# f29h85x_xbar_regs register map
Vendor: Texas Instruments
Peripheral module from a debugger description file (folder C29).
Registers are 32-bit, read-only, no defined reset value unless marked. A register's access mark holds for its fields unless they carry their own. Offsets are as the file gives them; lines under a group give offsets from that group; [hi:lo] are bit positions; {n}, {i} and the like mark numbered series; 'fields as' and 'values as' point back to an identical list; <NAME> marks a mode.

## XBAR_REGS — XBAR Registers
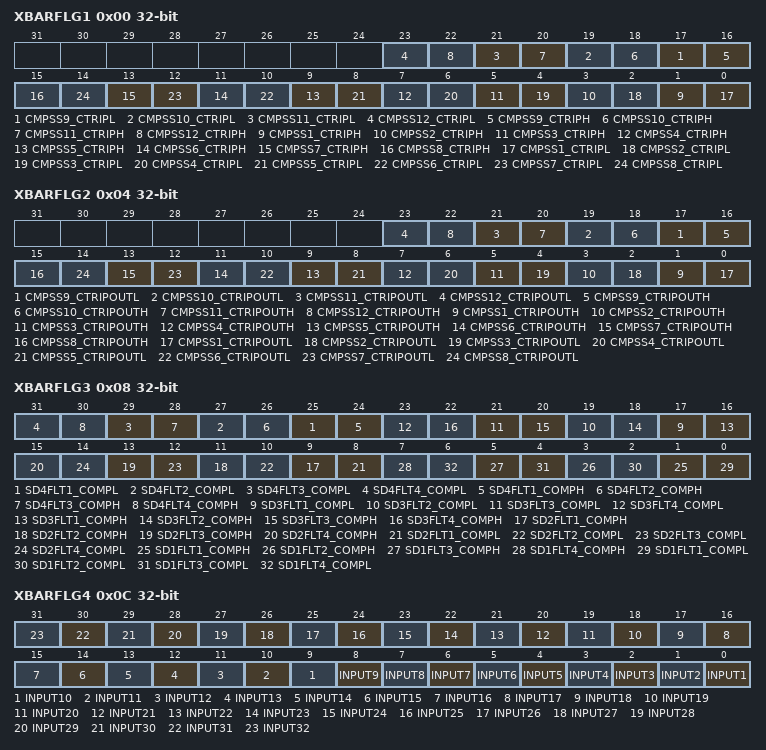
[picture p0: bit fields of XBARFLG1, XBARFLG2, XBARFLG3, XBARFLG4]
0x00 XBARFLG1 — X-Bar Input Flag Register 1
  [2n-1] CMPSS{n}_CTRIPL (n=9..12) — Input Flag for CMPSS{n}_CTRIPL Signal
  [2n-2] CMPSS{n}_CTRIPH (n=9..12) — Input Flag for CMPSS{n}_CTRIPH Signal
  [2n-1] CMPSS{n}_CTRIPH (n=1..8) — Input Flag for CMPSS{n}_CTRIPH Signal
  [2n-2] CMPSS{n}_CTRIPL (n=1..8) — Input Flag for CMPSS{n}_CTRIPL Signal
0x04 XBARFLG2 — X-Bar Input Flag Register 2
  [2n-1] CMPSS{n}_CTRIPOUTL (n=9..12) — Input Flag for CMPSS{n}_CTRIPOUTL Signal
  [2n-2] CMPSS{n}_CTRIPOUTH (n=9..12) — Input Flag for CMPSS{n}_CTRIPOUTH Signal
  [2n-1] CMPSS{n}_CTRIPOUTH (n=1..8) — Input Flag for CMPSS{n}_CTRIPOUTH Signal
  [2n-2] CMPSS{n}_CTRIPOUTL (n=1..8) — Input Flag for CMPSS{n}_CTRIPOUTL Signal
0x08 XBARFLG3 — X-Bar Input Flag Register 3
  [2n+23] SD4FLT{n}_COMPL (n=1..4) — Input Flag for SD4FLT{n}_COMPL Signal
  [2n+22] SD4FLT{n}_COMPH (n=1..4) — Input Flag for SD4FLT{n}_COMPH Signal
  [2n+15] SD3FLT{n}_COMPL (n=1..4) — Input Flag for SD3FLT{n}_COMPL Signal
  [2n+14] SD3FLT{n}_COMPH (n=1..4) — Input Flag for SD3FLT{n}_COMPH Signal
  [2n+7] SD2FLT{n}_COMPH (n=1..4) — Input Flag for SD2FLT{n}_COMPH Signal
  [2n+6] SD2FLT{n}_COMPL (n=1..4) — Input Flag for SD2FLT{n}_COMPL Signal
  [2n-1] SD1FLT{n}_COMPH (n=1..4) — Input Flag for SD1FLT{n}_COMPH Signal
  [2n-2] SD1FLT{n}_COMPL (n=1..4) — Input Flag for SD1FLT{n}_COMPL Signal
0x0C XBARFLG4 — X-Bar Input Flag Register 4
  [n-1] INPUT{n} (n=1..32) — Input Flag for INPUT{n} Signal
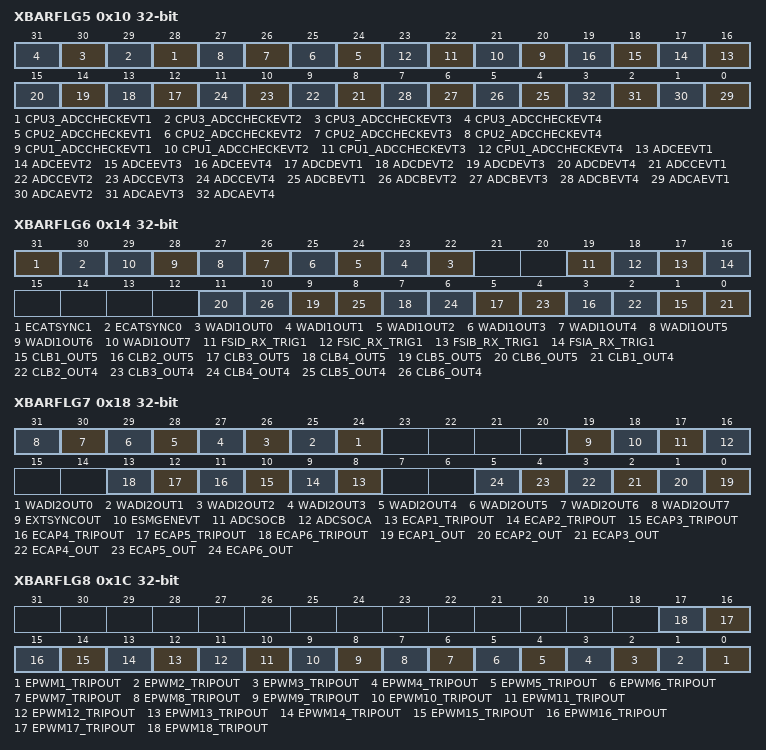
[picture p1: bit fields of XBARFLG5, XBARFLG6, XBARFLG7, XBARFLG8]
0x10 XBARFLG5 — X-Bar Input Flag Register 5
  [n+27] CPU3_ADCCHECKEVT{n} (n=1..4) — Input Flag for CPU3_ADCCHECKEVT{n} Signal
  [n+23] CPU2_ADCCHECKEVT{n} (n=1..4) — Input Flag for CPU2_ADCCHECKEVT{n} Signal
  [n+19] CPU1_ADCCHECKEVT{n} (n=1..4) — Input Flag for CPU1_ADCCHECKEVT{n} Signal
  [n+15] ADCEEVT{n} (n=1..4) — Input Flag for ADCEEVT{n} Signal
  [n+11] ADCDEVT{n} (n=1..4) — Input Flag for ADCDEVT{n} Signal
  [n+7] ADCCEVT{n} (n=1..4) — Input Flag for ADCCEVT{n} Signal
  [n+3] ADCBEVT{n} (n=1..4) — Input Flag for ADCBEVT{n} Signal
  [n-1] ADCAEVT{n} (n=1..4) — Input Flag for ADCAEVT{n} Signal
0x14 XBARFLG6 — X-Bar Input Flag Register 6
  [31] ECATSYNC1 — Input Latch for ECATSYNC1 Signal
  [30] ECATSYNC0 — Input Latch for ECATSYNC0 Signal
  [n+22] WADI1OUT{n} (n=0..7) — Input Flag for WADI1OUT{n} Signal
  [19] FSID_RX_TRIG1 — Input Flag for FSID_RX_TRIG1 Signal
  [18] FSIC_RX_TRIG1 — Input Flag for FSIC_RX_TRIG1 Signal
  [17] FSIB_RX_TRIG1 — Input Flag for FSIB_RX_TRIG1 Signal
  [16] FSIA_RX_TRIG1 — Input Flag for FSIA_RX_TRIG1 Signal
  [2n-1] CLB{n}_OUT5 (n=1..6) — Input Latch for CLB{n}_OUT5 Signal
  [2n-2] CLB{n}_OUT4 (n=1..6) — Input Latch for CLB{n}_OUT4 Signal
0x18 XBARFLG7 — X-Bar Input Flag Register 7
  [n+24] WADI2OUT{n} (n=0..7) — Input Flag for WADI2OUT{n} Signal
  [19] EXTSYNCOUT — Input Flag for EXTSYNCOUT Signal
  [18] ESMGENEVT — Input Flag for ESMGENEVT Signal
  [17] ADCSOCB — Input Flag for ADCSOCB Signal
  [16] ADCSOCA — Input Flag for ADCSOCA Signal
  [n+7] ECAP{n}_TRIPOUT (n=1..6) — Input Flag for ECAP{n}_TRIPOUT Signal
  [n-1] ECAP{n}_OUT (n=1..6) — Input Flag for ECAP{n}_OUT Signal
0x1C XBARFLG8 — X-Bar Input Flag Register 8
  [n-1] EPWM{n}_TRIPOUT (n=1..18) — Input Flag for EPWM{n}_TRIPOUT Signal
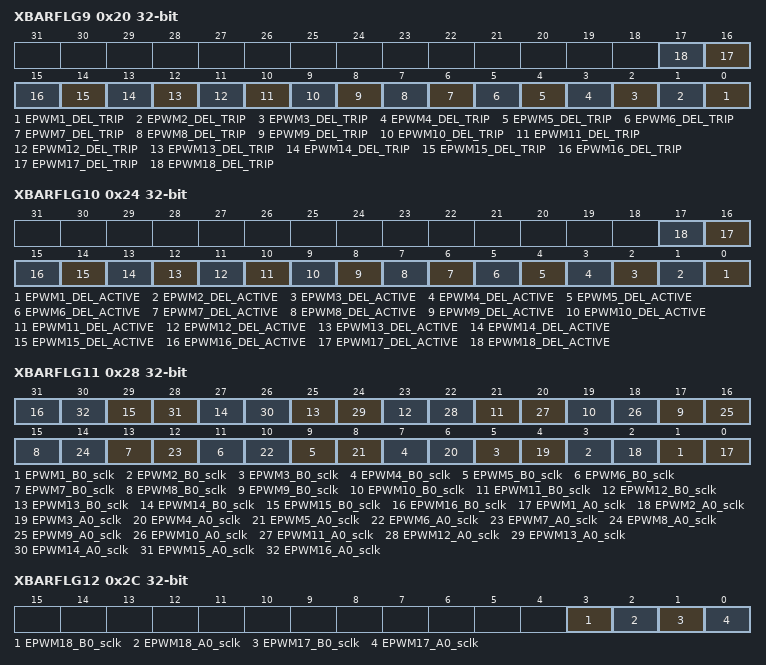
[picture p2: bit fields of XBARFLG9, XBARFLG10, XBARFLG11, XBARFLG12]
0x20 XBARFLG9 — X-Bar Input Flag Register 9
  [n-1] EPWM{n}_DEL_TRIP (n=1..18) — Input Flag for EPWM{n}_DEL_TRIP Signal
0x24 XBARFLG10 — X-Bar Input Flag Register 10
  [n-1] EPWM{n}_DEL_ACTIVE (n=1..18) — Input Flag for EPWM{n}_DEL_ACTIVE Signal
0x28 XBARFLG11 — X-Bar Input Flag Register 11
  [2n-1] EPWM{n}_B0_sclk (n=1..16) — Input Flag for EPWM{n}_B0_sclk Signal
  [2n-2] EPWM{n}_A0_sclk (n=1..16) — Input Flag for EPWM{n}_A0_sclk Signal
0x2C XBARFLG12 — X-Bar Input Flag Register 12
  [3] EPWM18_B0_sclk — Input Flag for EPWM18_B0_sclk Signal
  [2] EPWM18_A0_sclk — Input Flag for EPWM18_A0_sclk Signal
  [1] EPWM17_B0_sclk — Input Flag for EPWM17_B0_sclk Signal
  [0] EPWM17_A0_sclk — Input Flag for EPWM17_A0_sclk Signal
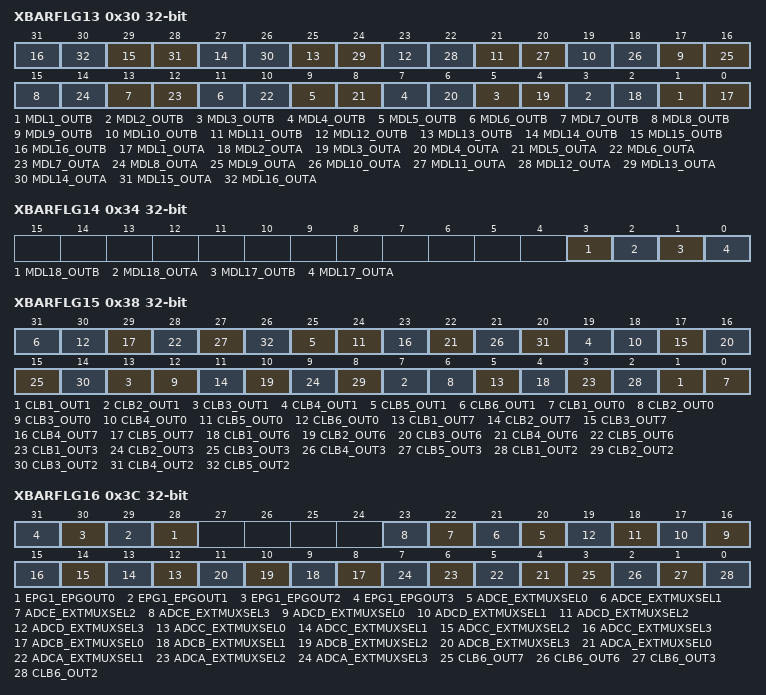
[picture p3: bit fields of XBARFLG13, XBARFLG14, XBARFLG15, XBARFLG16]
0x30 XBARFLG13 — X-Bar Input Flag Register 13
  [2n-1] MDL{n}_OUTB (n=1..16) — Input Flag for MDL{n}_OUTB Signal
  [2n-2] MDL{n}_OUTA (n=1..16) — Input Flag for MDL{n}_OUTA Signal
0x34 XBARFLG14 — X-Bar Input Flag Register 14
  [3] MDL18_OUTB — Input Flag for MDL18_OUTB Signal
  [2] MDL18_OUTA — Input Flag for MDL18_OUTA Signal
  [1] MDL17_OUTB — Input Flag for MDL17_OUTB Signal
  [0] MDL17_OUTA — Input Flag for MDL17_OUTA Signal
0x38 XBARFLG15 — X-Bar Input Flag Register 15
  [6n-5] CLB{n}_OUT1 (n=1..6) — Input Flag for CLB{n}_OUT1 Signal
  [6n-6] CLB{n}_OUT0 (n=1..6) — Input Flag for CLB{n}_OUT0 Signal
  [6n-1] CLB{n}_OUT7 (n=1..5) — Input Flag for CLB{n}_OUT7 Signal
  [6n-2] CLB{n}_OUT6 (n=1..5) — Input Flag for CLB{n}_OUT6 Signal
  [6n-3] CLB{n}_OUT3 (n=1..5) — Input Flag for CLB{n}_OUT3 Signal
  [6n-4] CLB{n}_OUT2 (n=1..5) — Input Flag for CLB{n}_OUT2 Signal
0x3C XBARFLG16 — X-Bar Input Flag Register 16
  [n+28] EPG1_EPGOUT{n} (n=0..3) — Input Flag for EPG1_EPGOUT{n} Signal
  [n+20] ADCE_EXTMUXSEL{n} (n=0..3) — Input Flag for ADCE_EXTMUXSEL{n} Signal
  [n+16] ADCD_EXTMUXSEL{n} (n=0..3) — Input Flag for ADCD_EXTMUXSEL{n} Signal
  [n+12] ADCC_EXTMUXSEL{n} (n=0..3) — Input Flag for ADCC_EXTMUXSEL{n} Signal
  [n+8] ADCB_EXTMUXSEL{n} (n=0..3) — Input Flag for ADCB_EXTMUXSEL{n} Signal
  [n+4] ADCA_EXTMUXSEL{n} (n=0..3) — Input Flag for ADCA_EXTMUXSEL{n} Signal
  [3] CLB6_OUT7 — Input Flag for CLB6_OUT7 Signal
  [2] CLB6_OUT6 — Input Flag for CLB6_OUT6 Signal
  [1] CLB6_OUT3 — Input Flag for CLB6_OUT3 Signal
  [0] CLB6_OUT2 — Input Flag for CLB6_OUT2 Signal
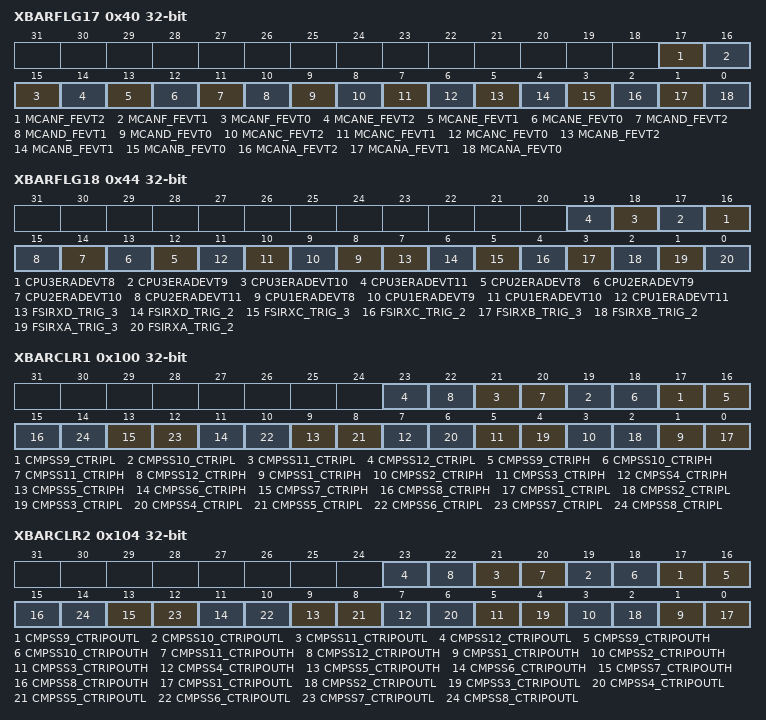
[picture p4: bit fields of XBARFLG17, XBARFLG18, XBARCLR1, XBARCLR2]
0x40 XBARFLG17 — X-Bar Input Flag Register 16
  [17] MCANF_FEVT2 — Input Flag for MCANF_FEVT2 Signal
  [16] MCANF_FEVT1 — Input Flag for MCANF_FEVT1 Signal
  [15] MCANF_FEVT0 — Input Flag for MCANF_FEVT0 Signal
  [14] MCANE_FEVT2 — Input Flag for MCANE_FEVT2 Signal
  [13] MCANE_FEVT1 — Input Flag for MCANE_FEVT1 Signal
  [12] MCANE_FEVT0 — Input Flag for MCANE_FEVT0 Signal
  [11] MCAND_FEVT2 — Input Flag for MCAND_FEVT2 Signal
  [10] MCAND_FEVT1 — Input Flag for MCAND_FEVT1 Signal
  [9] MCAND_FEVT0 — Input Flag for MCAND_FEVT0 Signal
  [8] MCANC_FEVT2 — Input Flag for MCANC_FEVT2 Signal
  [7] MCANC_FEVT1 — Input Flag for MCANC_FEVT1 Signal
  [6] MCANC_FEVT0 — Input Flag for MCANC_FEVT0 Signal
  [5] MCANB_FEVT2 — Input Flag for MCANB_FEVT2 Signal
  [4] MCANB_FEVT1 — Input Flag for MCANB_FEVT1 Signal
  [3] MCANB_FEVT0 — Input Flag for MCANB_FEVT0 Signal
  [2] MCANA_FEVT2 — Input Flag for MCANA_FEVT2 Signal
  [1] MCANA_FEVT1 — Input Flag for MCANA_FEVT1 Signal
  [0] MCANA_FEVT0 — Input Flag for MCANA_FEVT0 Signal
0x44 XBARFLG18 — X-Bar Input Flag Register 16
  [n+8] CPU3ERADEVT{n} (n=8..11) — Input Flag for CPU3ERADEVT{n} Signal
  [n+4] CPU2ERADEVT{n} (n=8..11) — Input Flag for CPU2ERADEVT{n} Signal
  [n] CPU1ERADEVT{n} (n=8..11) — Input Flag for CPU1ERADEVT{n} Signal
  [7] FSIRXD_TRIG_3 — Input Flag for FSIRXD_TRIG_3 Signal
  [6] FSIRXD_TRIG_2 — Input Flag for FSIRXD_TRIG_2 Signal
  [5] FSIRXC_TRIG_3 — Input Flag for FSIRXC_TRIG_3 Signal
  [4] FSIRXC_TRIG_2 — Input Flag for FSIRXC_TRIG_2 Signal
  [3] FSIRXB_TRIG_3 — Input Flag for FSIRXB_TRIG_3 Signal
  [2] FSIRXB_TRIG_2 — Input Flag for FSIRXB_TRIG_2 Signal
  [1] FSIRXA_TRIG_3 — Input Flag for FSIRXA_TRIG_3 Signal
  [0] FSIRXA_TRIG_2 — Input Flag for FSIRXA_TRIG_2 Signal
0x100 XBARCLR1 rw — X-Bar Input Flag Clear Register 1
  [2n-1] CMPSS{n}_CTRIPL (n=9..12) — Input Flag Clear for CMPSS{n}_CTRIPL Signal
  [2n-2] CMPSS{n}_CTRIPH (n=9..12) — Input Flag Clear for CMPSS{n}_CTRIPH Signal
  [2n-1] CMPSS{n}_CTRIPH (n=1..8) — Input Flag Clear for CMPSS{n}_CTRIPH Signal
  [2n-2] CMPSS{n}_CTRIPL (n=1..8) — Input Flag Clear for CMPSS{n}_CTRIPL Signal
0x104 XBARCLR2 rw — X-Bar Input Flag Clear Register 2
  [2n-1] CMPSS{n}_CTRIPOUTL (n=9..12) — Input Flag clear for CMPSS{n}_CTRIPOUTL Signal
  [2n-2] CMPSS{n}_CTRIPOUTH (n=9..12) — Input Flag clear for CMPSS{n}_CTRIPOUTH Signal
  [2n-1] CMPSS{n}_CTRIPOUTH (n=1..8) — Input Flag clear for CMPSS{n}_CTRIPOUTH Signal
  [2n-2] CMPSS{n}_CTRIPOUTL (n=1..8) — Input Flag clear for CMPSS{n}_CTRIPOUTL Signal
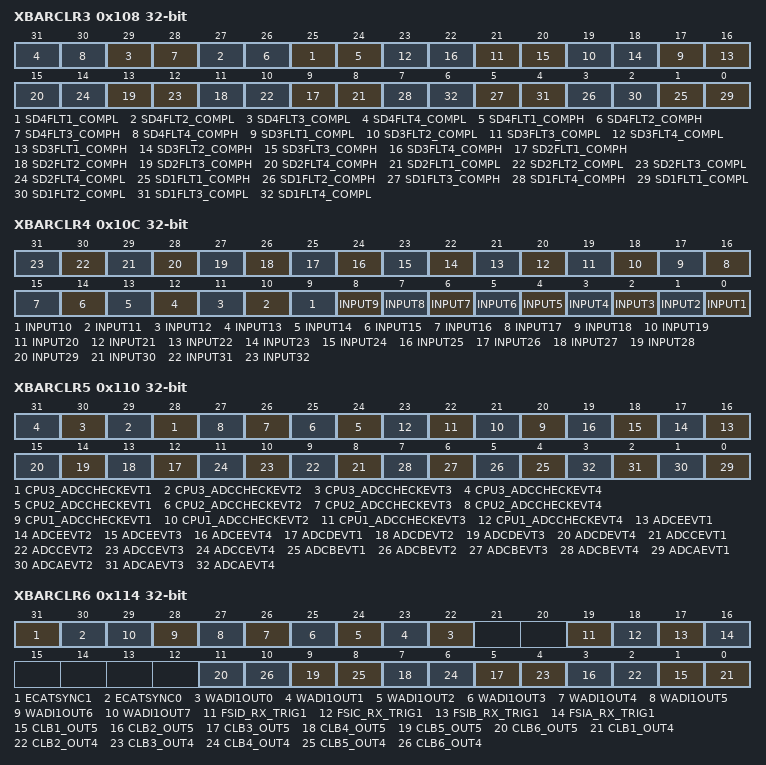
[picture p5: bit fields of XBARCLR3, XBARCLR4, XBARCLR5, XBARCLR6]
0x108 XBARCLR3 rw — X-Bar Input Flag Clear Register 3
  [2n+23] SD4FLT{n}_COMPL (n=1..4) — Input Flag Clear for SD4FLT{n}_COMPL Signal
  [2n+22] SD4FLT{n}_COMPH (n=1..4) — Input Flag Clear for SD4FLT{n}_COMPH Signal
  [2n+15] SD3FLT{n}_COMPL (n=1..4) — Input Flag Clear for SD3FLT{n}_COMPL Signal
  [2n+14] SD3FLT{n}_COMPH (n=1..4) — Input Flag Clear for SD3FLT{n}_COMPH Signal
  [2n+7] SD2FLT{n}_COMPH (n=1..4) — Input Flag Clear for SD2FLT{n}_COMPH Signal
  [2n+6] SD2FLT{n}_COMPL (n=1..4) — Input Flag Clear for SD2FLT{n}_COMPL Signal
  [2n-1] SD1FLT{n}_COMPH (n=1..4) — Input Flag Clear for SD1FLT{n}_COMPH Signal
  [2n-2] SD1FLT{n}_COMPL (n=1..4) — Input Flag Clear for SD1FLT{n}_COMPL Signal
0x10C XBARCLR4 rw — X-Bar Input Flag Clear Register 4
  [n-1] INPUT{n} (n=1..32) — Input Flag Clear for INPUT{n} Signal
0x110 XBARCLR5 rw — X-Bar Input Flag Clear Register 5
  [n+27] CPU3_ADCCHECKEVT{n} (n=1..4) — Input Flag Clear for CPU3_ADCCHECKEVT{n} Signal
  [n+23] CPU2_ADCCHECKEVT{n} (n=1..4) — Input Flag Clear for CPU2_ADCCHECKEVT{n} Signal
  [n+19] CPU1_ADCCHECKEVT{n} (n=1..4) — Input Flag Clear for CPU1_ADCCHECKEVT{n} Signal
  [n+15] ADCEEVT{n} (n=1..4) — Input Flag Clear for ADCEEVT{n} Signal
  [n+11] ADCDEVT{n} (n=1..4) — Input Flag Clear for ADCDEVT{n} Signal
  [n+7] ADCCEVT{n} (n=1..4) — Input Flag Clear for ADCCEVT{n} Signal
  [n+3] ADCBEVT{n} (n=1..4) — Input Flag Clear for ADCBEVT{n} Signal
  [n-1] ADCAEVT{n} (n=1..4) — Input Flag Clear for ADCAEVT{n} Signal
0x114 XBARCLR6 rw — X-Bar Input Flag Clear Register 6
  [31] ECATSYNC1 — Input Flag Clear for ECATSYNC1 Signal
  [30] ECATSYNC0 — Input Flag Clear for ECATSYNC0 Signal
  [n+22] WADI1OUT{n} (n=0..7) — Input Flag Clear for WADI1OUT{n} Signal
  [19] FSID_RX_TRIG1 — Input Flag Clear for FSID_RX_TRIG1 Signal
  [18] FSIC_RX_TRIG1 — Input Flag Clear for FSIC_RX_TRIG1 Signal
  [17] FSIB_RX_TRIG1 — Input Flag Clear for FSIB_RX_TRIG1 Signal
  [16] FSIA_RX_TRIG1 — Input Flag Clear for FSIA_RX_TRIG1 Signal
  [2n-1] CLB{n}_OUT5 (n=1..6) — Input Flag Clear for CLB{n}_OUT5 Signal
  [2n-2] CLB{n}_OUT4 (n=1..6) — Input Flag Clear for CLB{n}_OUT4 Signal
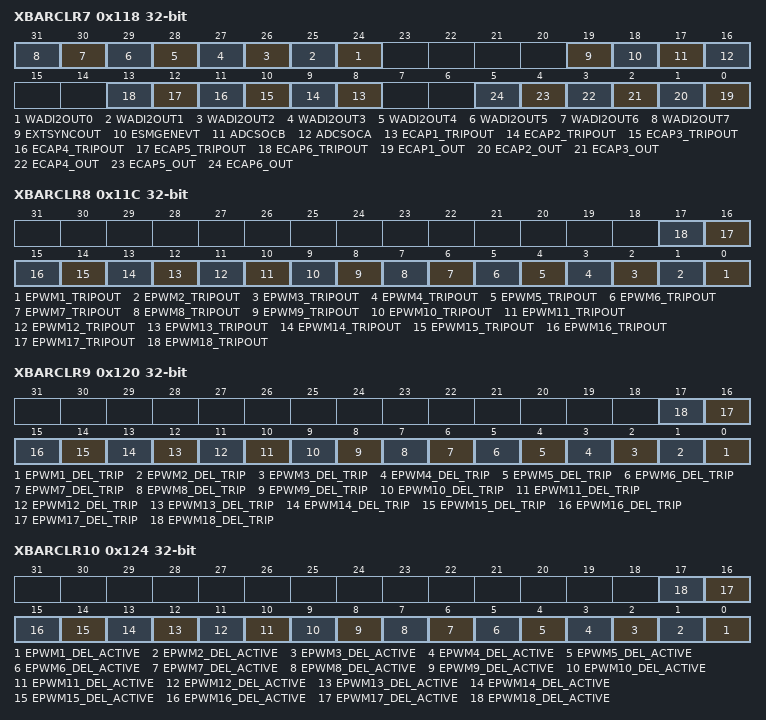
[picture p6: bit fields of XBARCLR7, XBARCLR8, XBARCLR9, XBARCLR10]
0x118 XBARCLR7 rw — X-Bar Input Flag Clear Register 7
  [n+24] WADI2OUT{n} (n=0..7) — Input Flag Clear for WADI2OUT{n} Signal
  [19] EXTSYNCOUT — Input Flag Clear for EXTSYNCOUT Signal
  [18] ESMGENEVT — Input Flag Clear for ESMGENEVT Signal
  [17] ADCSOCB — Input Flag Clear for ADCSOCB Signal
  [16] ADCSOCA — Input Flag Clear for ADCSOCA Signal
  [n+7] ECAP{n}_TRIPOUT (n=1..6) — Input Flag Clear for ECAP{n}_TRIPOUT Signal
  [n-1] ECAP{n}_OUT (n=1..6) — Input Flag Clear for ECAP{n}_OUT Signal
0x11C XBARCLR8 rw — X-Bar Input Flag Clear Register 8
  [n-1] EPWM{n}_TRIPOUT (n=1..18) — Input Flag clear for EPWM{n}_TRIPOUT Signal
0x120 XBARCLR9 rw — X-Bar Input Flag Clear Register 9
  [n-1] EPWM{n}_DEL_TRIP (n=1..18) — Input Flag clear for EPWM{n}_DEL_TRIP Signal
0x124 XBARCLR10 rw — X-Bar Input Flag Clear Register 10
  [n-1] EPWM{n}_DEL_ACTIVE (n=1..18) — Input Flag clear for EPWM{n}_DEL_ACTIVE Signal
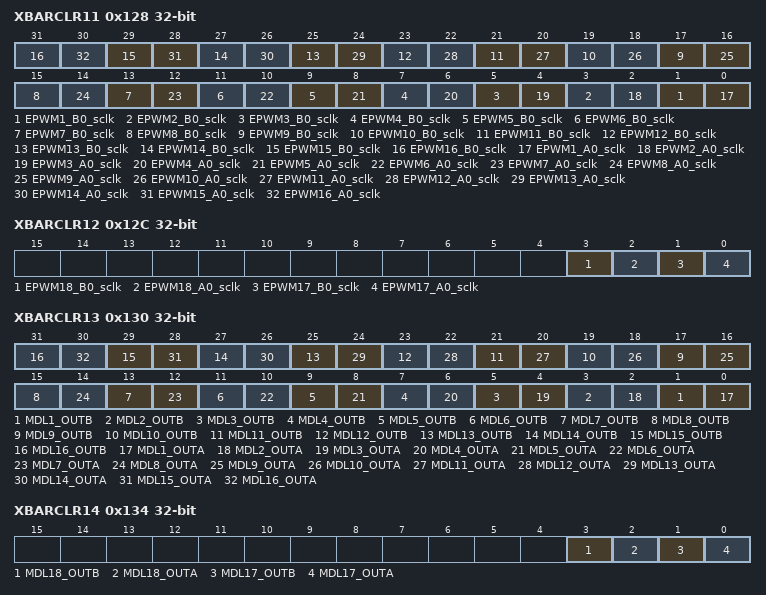
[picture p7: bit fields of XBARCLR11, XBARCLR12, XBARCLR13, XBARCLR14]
0x128 XBARCLR11 rw — X-Bar Input Flag Clear Register 11
  [2n-1] EPWM{n}_B0_sclk (n=1..16) — Input Flag clear for EPWM{n}_B0_sclk Signal
  [2n-2] EPWM{n}_A0_sclk (n=1..16) — Input Flag clear for EPWM{n}_A0_sclk Signal
0x12C XBARCLR12 rw — X-Bar Input Flag Clear Register 12
  [3] EPWM18_B0_sclk — Input Flag clear for EPWM18_B0_sclk Signal
  [2] EPWM18_A0_sclk — Input Flag clear for EPWM18_A0_sclk Signal
  [1] EPWM17_B0_sclk — Input Flag clear for EPWM17_B0_sclk Signal
  [0] EPWM17_A0_sclk — Input Flag clear for EPWM17_A0_sclk Signal
0x130 XBARCLR13 rw — X-Bar Input Flag Clear Register 13
  [2n-1] MDL{n}_OUTB (n=1..16) — Input Flag clear for MDL{n}_OUTB Signal
  [2n-2] MDL{n}_OUTA (n=1..16) — Input Flag clear for MDL{n}_OUTA Signal
0x134 XBARCLR14 rw — X-Bar Input Flag Clear Register 14
  [3] MDL18_OUTB — Input Flag clear for MDL18_OUTB Signal
  [2] MDL18_OUTA — Input Flag clear for MDL18_OUTA Signal
  [1] MDL17_OUTB — Input Flag clear for MDL17_OUTB Signal
  [0] MDL17_OUTA — Input Flag clear for MDL17_OUTA Signal
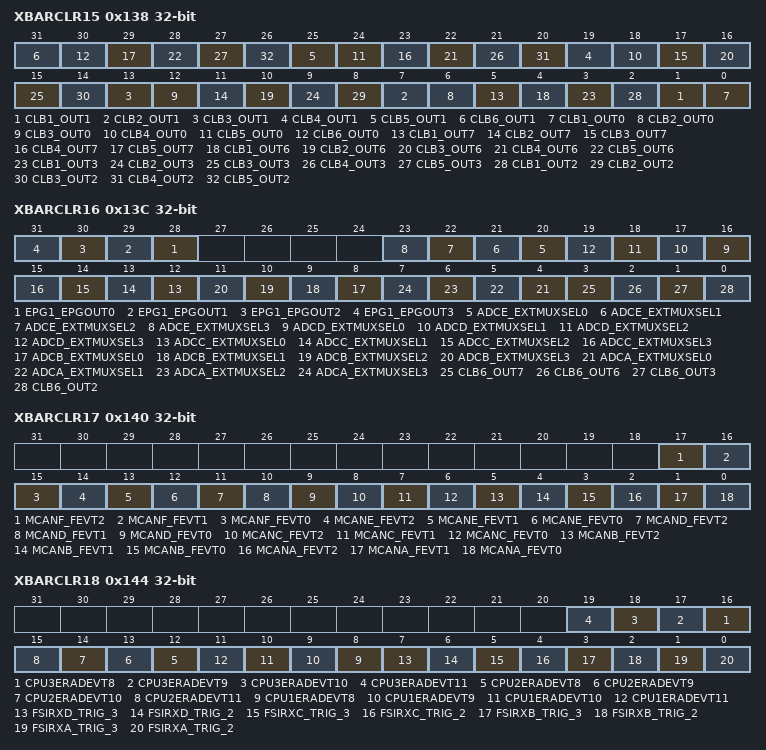
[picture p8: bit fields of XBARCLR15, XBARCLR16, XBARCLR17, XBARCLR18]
0x138 XBARCLR15 rw — X-Bar Input Flag Clear Register 15
  [6n-5] CLB{n}_OUT1 (n=1..6) — Input Flag clear for CLB{n}_OUT1 Signal
  [6n-6] CLB{n}_OUT0 (n=1..6) — Input Flag clear for CLB{n}_OUT0 Signal
  [6n-1] CLB{n}_OUT7 (n=1..5) — Input Flag clear for CLB{n}_OUT7 Signal
  [6n-2] CLB{n}_OUT6 (n=1..5) — Input Flag clear for CLB{n}_OUT6 Signal
  [6n-3] CLB{n}_OUT3 (n=1..5) — Input Flag clear for CLB{n}_OUT3 Signal
  [6n-4] CLB{n}_OUT2 (n=1..5) — Input Flag clear for CLB{n}_OUT2 Signal
0x13C XBARCLR16 rw — X-Bar Input Flag Clear Register 15
  [n+28] EPG1_EPGOUT{n} (n=0..3) — Input Flag clear for EPG1_EPGOUT{n} Signal
  [n+20] ADCE_EXTMUXSEL{n} (n=0..3) — Input Flag clear for ADCE_EXTMUXSEL{n} Signal
  [n+16] ADCD_EXTMUXSEL{n} (n=0..3) — Input Flag clear for ADCD_EXTMUXSEL{n} Signal
  [n+12] ADCC_EXTMUXSEL{n} (n=0..3) — Input Flag clear for ADCC_EXTMUXSEL{n} Signal
  [n+8] ADCB_EXTMUXSEL{n} (n=0..3) — Input Flag clear for ADCB_EXTMUXSEL{n} Signal
  [n+4] ADCA_EXTMUXSEL{n} (n=0..3) — Input Flag clear for ADCA_EXTMUXSEL{n} Signal
  [3] CLB6_OUT7 — Input Flag clear for CLB6_OUT7 Signal
  [2] CLB6_OUT6 — Input Flag clear for CLB6_OUT6 Signal
  [1] CLB6_OUT3 — Input Flag clear for CLB6_OUT3 Signal
  [0] CLB6_OUT2 — Input Flag clear for CLB6_OUT2 Signal
0x140 XBARCLR17 rw — X-Bar Input Flag Clear Register 16
  [17] MCANF_FEVT2 — Input Flag clear for MCANF_FEVT2 Signal
  [16] MCANF_FEVT1 — Input Flag clear for MCANF_FEVT1 Signal
  [15] MCANF_FEVT0 — Input Flag clear for MCANF_FEVT0 Signal
  [14] MCANE_FEVT2 — Input Flag clear for MCANE_FEVT2 Signal
  [13] MCANE_FEVT1 — Input Flag clear for MCANE_FEVT1 Signal
  [12] MCANE_FEVT0 — Input Flag clear for MCANE_FEVT0 Signal
  [11] MCAND_FEVT2 — Input Flag clear for MCAND_FEVT2 Signal
  [10] MCAND_FEVT1 — Input Flag clear for MCAND_FEVT1 Signal
  [9] MCAND_FEVT0 — Input Flag clear for MCAND_FEVT0 Signal
  [8] MCANC_FEVT2 — Input Flag clear for MCANC_FEVT2 Signal
  [7] MCANC_FEVT1 — Input Flag clear for MCANC_FEVT1 Signal
  [6] MCANC_FEVT0 — Input Flag clear for MCANC_FEVT0 Signal
  [5] MCANB_FEVT2 — Input Flag clear for MCANB_FEVT2 Signal
  [4] MCANB_FEVT1 — Input Flag clear for MCANB_FEVT1 Signal
  [3] MCANB_FEVT0 — Input Flag clear for MCANB_FEVT0 Signal
  [2] MCANA_FEVT2 — Input Flag clear for MCANA_FEVT2 Signal
  [1] MCANA_FEVT1 — Input Flag clear for MCANA_FEVT1 Signal
  [0] MCANA_FEVT0 — Input Flag clear for MCANA_FEVT0 Signal
0x144 XBARCLR18 rw — X-Bar Input Flag Clear Register 16
  [n+8] CPU3ERADEVT{n} (n=8..11) — Input Flag clear for CPU3ERADEVT{n} Signal
  [n+4] CPU2ERADEVT{n} (n=8..11) — Input Flag clear for CPU2ERADEVT{n} Signal
  [n] CPU1ERADEVT{n} (n=8..11) — Input Flag clear for CPU1ERADEVT{n} Signal
  [7] FSIRXD_TRIG_3 — Input Flag clear for FSIRXD_TRIG_3 Signal
  [6] FSIRXD_TRIG_2 — Input Flag clear for FSIRXD_TRIG_2 Signal
  [5] FSIRXC_TRIG_3 — Input Flag clear for FSIRXC_TRIG_3 Signal
  [4] FSIRXC_TRIG_2 — Input Flag clear for FSIRXC_TRIG_2 Signal
  [3] FSIRXB_TRIG_3 — Input Flag clear for FSIRXB_TRIG_3 Signal
  [2] FSIRXB_TRIG_2 — Input Flag clear for FSIRXB_TRIG_2 Signal
  [1] FSIRXA_TRIG_3 — Input Flag clear for FSIRXA_TRIG_3 Signal
  [0] FSIRXA_TRIG_2 — Input Flag clear for FSIRXA_TRIG_2 Signal
